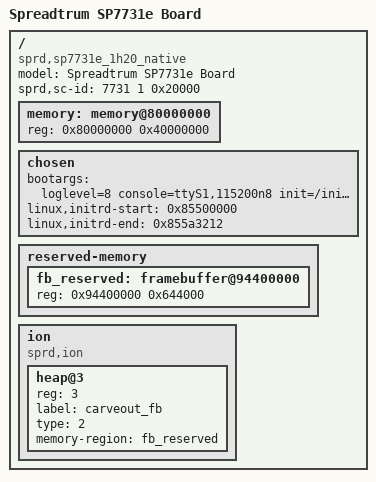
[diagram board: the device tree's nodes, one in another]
/*
 * Spreadtrum SC9833 FPGA board DTS file
 *
 * Copyright (C) 2015-2016, Spreadtrum Communications Inc.
 *
 * This file is licensed under a dual GPLv2 or X11 license.
 */

/dts-v1/;


/ {
	model = "Spreadtrum SP7731e Board";

	compatible = "sprd,sp7731e_1h20_native", "sprd,pike2";

	sprd,sc-id = <7731 1 0x20000>;

	memory: memory@80000000 {
		device_type = "memory";
		reg = <0x80000000 0x40000000>;
	};

	chosen {
		bootargs = "loglevel=8 console=ttyS1,115200n8 init=/init root=/dev/ram0 rw androidboot.hardware=sp7731efpga";
		linux,initrd-start = <0x85500000>;
		linux,initrd-end = <0x855a3212>;
	};

	reserved-memory {
		#address-cells = <1>;
		#size-cells = <1>;
		ranges;

		fb_reserved: framebuffer@94400000{
			reg = <0x94400000 0x644000>;
			/* the original framebuffer addr  <0x9ea00000 0x1600000> confilct with
			* uboot<9f000000 ffffff>, change range only for FPGA debug */
		};
	};

	ion {
		compatible = "sprd,ion";
		#address-cells = <1>;
		#size-cells = <0>;

		heap@3 {
			reg = <3>;
			label = "carveout_fb";
			type = <2>;
			memory-region = <&fb_reserved>;
		};
	};
};

